AUTOSAR XML (schema 00046)
package /ComponentTypes
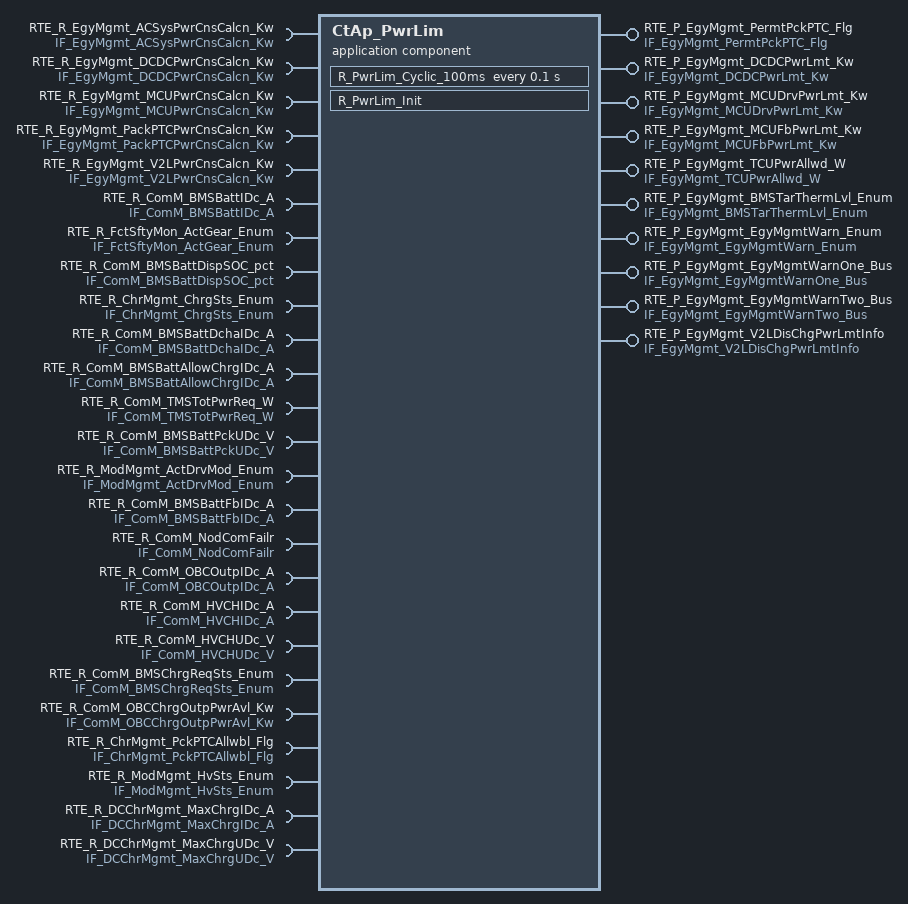
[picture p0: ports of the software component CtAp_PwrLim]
  application sw component type CtAp_PwrLim
    19 x require port:
      RTE_R_EgyMgmt_ACSysPwrCnsCalcn_Kw: nonqueued-receiver-com-spec{data-element=tec_EgyMgmt_ACSysPwrCnsCalcn_Kw, filter=data-filter-type=ALWAYS, init-value=0}, required-interface=IF_EgyMgmt_ACSysPwrCnsCalcn_Kw
      RTE_R_EgyMgmt_DCDCPwrCnsCalcn_Kw: nonqueued-receiver-com-spec{data-element=tec_EgyMgmt_DCDCPwrCnsCalcn_Kw, filter=data-filter-type=ALWAYS, init-value=0}, required-interface=IF_EgyMgmt_DCDCPwrCnsCalcn_Kw
      RTE_R_EgyMgmt_MCUPwrCnsCalcn_Kw: nonqueued-receiver-com-spec{data-element=tec_EgyMgmt_MCUPwrCnsCalcn_Kw, filter=data-filter-type=ALWAYS, init-value=0}, required-interface=IF_EgyMgmt_MCUPwrCnsCalcn_Kw
      RTE_R_EgyMgmt_PackPTCPwrCnsCalcn_Kw: nonqueued-receiver-com-spec{data-element=tec_EgyMgmt_PackPTCPwrCnsCalcn_Kw, filter=data-filter-type=ALWAYS, init-value=0}, required-interface=IF_EgyMgmt_PackPTCPwrCnsCalcn_Kw
      RTE_R_EgyMgmt_V2LPwrCnsCalcn_Kw: nonqueued-receiver-com-spec{data-element=tec_EgyMgmt_V2LPwrCnsCalcn_Kw, filter=data-filter-type=ALWAYS, init-value=0}, required-interface=IF_EgyMgmt_V2LPwrCnsCalcn_Kw
      RTE_R_ComM_BMSBattIDc_A: nonqueued-receiver-com-spec{data-element=tec_ComM_BMSBattIDc_A, filter=data-filter-type=ALWAYS, init-value=0}, required-interface=IF_ComM_BMSBattIDc_A
      RTE_R_FctSftyMon_ActGear_Enum: nonqueued-receiver-com-spec{data-element=tec_FctSftyMon_ActGear_Enum, filter=data-filter-type=ALWAYS, init-value=0}, required-interface=IF_FctSftyMon_ActGear_Enum
      RTE_R_ComM_BMSBattDispSOC_pct: nonqueued-receiver-com-spec{data-element=tec_ComM_BMSBattDispSOC_pct, filter=data-filter-type=ALWAYS, init-value=0}, required-interface=IF_ComM_BMSBattDispSOC_pct
      RTE_R_ChrMgmt_ChrgSts_Enum: nonqueued-receiver-com-spec{data-element=tec_ChrMgmt_ChrgSts_Enum, filter=data-filter-type=ALWAYS, init-value=0}, required-interface=IF_ChrMgmt_ChrgSts_Enum
      RTE_R_ComM_BMSBattDchaIDc_A: nonqueued-receiver-com-spec{data-element=tec_ComM_BMSBattDchaIDc_A, filter=data-filter-type=ALWAYS, init-value=0}, required-interface=IF_ComM_BMSBattDchaIDc_A
      RTE_R_ComM_BMSBattAllowChrgIDc_A: nonqueued-receiver-com-spec{data-element=tec_ComM_BMSBattAllowChrgIDc_A, filter=data-filter-type=ALWAYS, init-value=0}, required-interface=IF_ComM_BMSBattAllowChrgIDc_A
      RTE_R_ComM_TMSTotPwrReq_W: nonqueued-receiver-com-spec{data-element=tec_ComM_TMSTotPwrReq_W, filter=data-filter-type=ALWAYS, init-value=0}, required-interface=IF_ComM_TMSTotPwrReq_W
      RTE_R_ComM_BMSBattPckUDc_V: nonqueued-receiver-com-spec{data-element=tec_ComM_BMSBattPckUDc_V, filter=data-filter-type=ALWAYS, init-value=0}, required-interface=IF_ComM_BMSBattPckUDc_V
      RTE_R_ModMgmt_ActDrvMod_Enum: nonqueued-receiver-com-spec{data-element=tec_ModMgmt_ActDrvMod_Enum, filter=data-filter-type=ALWAYS, init-value=0}, required-interface=IF_ModMgmt_ActDrvMod_Enum
      RTE_R_ComM_BMSBattFbIDc_A: nonqueued-receiver-com-spec{data-element=tec_ComM_BMSBattFbIDc_A, filter=data-filter-type=ALWAYS, init-value=0}, required-interface=IF_ComM_BMSBattFbIDc_A
      RTE_R_ComM_NodComFailr: required-interface=IF_ComM_NodComFailr
        required-com-specs:
          data-element=tec_ComM_SGWNodComFailr_Flg, filter=data-filter-type=ALWAYS, init-value=0
          data-element=tec_ComM_CGWNodComFailr_Flg, filter=data-filter-type=ALWAYS, init-value=0
          data-element=tec_ComM_TCUNodComFailr_Flg, filter=data-filter-type=ALWAYS, init-value=0
          data-element=tec_ComM_BCMNodComFailr_Flg, filter=data-filter-type=ALWAYS, init-value=0
          data-element=tec_ComM_PRNDNodComFailr_Flg, filter=data-filter-type=ALWAYS, init-value=0
          data-element=tec_ComM_IVINodComFailr_Flg, filter=data-filter-type=ALWAYS, init-value=0
          data-element=tec_ComM_DCDCNodComFailr_Flg, filter=data-filter-type=ALWAYS, init-value=0
          data-element=tec_ComM_OBCNodComFailr_Flg, filter=data-filter-type=ALWAYS, init-value=0
          data-element=tec_ComM_CHIBSNodComFailr_Flg, filter=data-filter-type=ALWAYS, init-value=0
          data-element=tec_ComM_MCUNodComFailr_Flg, filter=data-filter-type=ALWAYS, init-value=0
          data-element=tec_ComM_EVCOMNodComFailr_Flg, filter=data-filter-type=ALWAYS, init-value=0
          data-element=tec_ComM_EPTIBSNodComFailr_Flg, filter=data-filter-type=ALWAYS, init-value=0
          data-element=tec_ComM_DCMNodComFailr_Flg, filter=data-filter-type=ALWAYS, init-value=0
          data-element=tec_ComM_BMSNodComFailr_Flg, filter=data-filter-type=ALWAYS, init-value=0
          data-element=tec_ComM_ACUNodComFailr_Flg, filter=data-filter-type=ALWAYS, init-value=0
          data-element=tec_ComM_APTCNodComFailr_Flg, filter=data-filter-type=ALWAYS, init-value=0
          data-element=tec_ComM_ADCUNodComFailr_Flg, filter=data-filter-type=ALWAYS, init-value=0
          data-element=tec_ComM_DCMRRNodComFailr_Flg, filter=data-filter-type=ALWAYS, init-value=0
          data-element=tec_ComM_DCMRLNodComFailr_Flg, filter=data-filter-type=ALWAYS, init-value=0
          data-element=tec_ComM_DCMFRNodComFailr_Flg, filter=data-filter-type=ALWAYS, init-value=0
          data-element=tec_ComM_DCMFLNodComFailr_Flg, filter=data-filter-type=ALWAYS, init-value=0
          data-element=tec_ComM_SGWCHNodComFailr_Flg, init-value=0
      RTE_R_ComM_OBCOutpIDc_A: nonqueued-receiver-com-spec{data-element=tec_ComM_OBCOutpIDc_A, filter=data-filter-type=ALWAYS, init-value=0}, required-interface=IF_ComM_OBCOutpIDc_A
      RTE_R_ComM_HVCHIDc_A: nonqueued-receiver-com-spec{data-element=tec_ComM_HVCHIDc_A, filter=data-filter-type=ALWAYS, init-value=0}, required-interface=IF_ComM_HVCHIDc_A
      RTE_R_ComM_HVCHUDc_V: nonqueued-receiver-com-spec{data-element=tec_ComM_HVCHUDc_V, filter=data-filter-type=ALWAYS, init-value=0}, required-interface=IF_ComM_HVCHUDc_V
    10 x provide port:
      RTE_P_EgyMgmt_PermtPckPTC_Flg: nonqueued-sender-com-spec{data-element=tec_EgyMgmt_PermtPckPTC_Flg, init-value=0}, provided-interface=IF_EgyMgmt_PermtPckPTC_Flg
      RTE_P_EgyMgmt_DCDCPwrLmt_Kw: nonqueued-sender-com-spec{data-element=tec_EgyMgmt_DCDCPwrLmt_Kw, init-value=0}, provided-interface=IF_EgyMgmt_DCDCPwrLmt_Kw
      RTE_P_EgyMgmt_MCUDrvPwrLmt_Kw: nonqueued-sender-com-spec{data-element=tec_EgyMgmt_MCUDrvPwrLmt_Kw, init-value=0}, provided-interface=IF_EgyMgmt_MCUDrvPwrLmt_Kw
      RTE_P_EgyMgmt_MCUFbPwrLmt_Kw: nonqueued-sender-com-spec{data-element=tec_EgyMgmt_MCUFbPwrLmt_Kw, init-value=0}, provided-interface=IF_EgyMgmt_MCUFbPwrLmt_Kw
      RTE_P_EgyMgmt_TCUPwrAllwd_W: nonqueued-sender-com-spec{data-element=tec_EgyMgmt_TCUPwrAllwd_W, init-value=0}, provided-interface=IF_EgyMgmt_TCUPwrAllwd_W
      RTE_P_EgyMgmt_BMSTarThermLvl_Enum: nonqueued-sender-com-spec{data-element=tec_EgyMgmt_BMSTarThermLvl_Enum, init-value=0}, provided-interface=IF_EgyMgmt_BMSTarThermLvl_Enum
      RTE_P_EgyMgmt_EgyMgmtWarn_Enum: nonqueued-sender-com-spec{data-element=tec_EgyMgmt_EgyMgmtWarn_Enum, init-value=0}, provided-interface=IF_EgyMgmt_EgyMgmtWarn_Enum
      RTE_P_EgyMgmt_EgyMgmtWarnOne_Bus: nonqueued-sender-com-spec{data-element=tec_EgyMgmt_EgyMgmtWarnOne_Bus, init-value=fields=[EgyMgmt_MonStatEgyMgmtWarnOne:0, EgyMgmt_MonResEgyMgmtWarnOne:0, EgyMgmt_ErrStatEgyMgmtWarnOne:0, EgyMgmt_ErrResEgyMgmtWarnOne:0]}, provided-interface=IF_EgyMgmt_EgyMgmtWarnOne_Bus
      RTE_P_EgyMgmt_EgyMgmtWarnTwo_Bus: nonqueued-sender-com-spec{data-element=tec_EgyMgmt_EgyMgmtWarnTwo_Bus, init-value=fields=[EgyMgmt_MonStatEgyMgmtWarnTwo:0, EgyMgmt_MonResEgyMgmtWarnTwo:0, EgyMgmt_ErrStatEgyMgmtWarnTwo:0, EgyMgmt_ErrResEgyMgmtWarnTwo:0]}, provided-interface=IF_EgyMgmt_EgyMgmtWarnTwo_Bus
      RTE_P_EgyMgmt_V2LDisChgPwrLmtInfo: nonqueued-sender-com-spec{data-element=tec_EgyMgmt_V2LDisChgPwrLmtInfo, init-value=0}, provided-interface=IF_EgyMgmt_V2LDisChgPwrLmtInfo
    6 x require port:
      RTE_R_ComM_BMSChrgReqSts_Enum: nonqueued-receiver-com-spec{data-element=tec_ComM_BMSChrgReqSts_Enum, filter=data-filter-type=ALWAYS, init-value=0}, required-interface=IF_ComM_BMSChrgReqSts_Enum
      RTE_R_ComM_OBCChrgOutpPwrAvl_Kw: nonqueued-receiver-com-spec{data-element=tec_ComM_OBCChrgOutpPwrAvl_Kw, filter=data-filter-type=ALWAYS, init-value=0}, required-interface=IF_ComM_OBCChrgOutpPwrAvl_Kw
      RTE_R_ChrMgmt_PckPTCAllwbl_Flg: nonqueued-receiver-com-spec{data-element=tec_ChrMgmt_PckPTCAllwbl_Flg, filter=data-filter-type=ALWAYS, init-value=0}, required-interface=IF_ChrMgmt_PckPTCAllwbl_Flg
      RTE_R_ModMgmt_HvSts_Enum: nonqueued-receiver-com-spec{data-element=tec_ModMgmt_HvSts_Enum, filter=data-filter-type=ALWAYS, init-value=0}, required-interface=IF_ModMgmt_HvSts_Enum
      RTE_R_DCChrMgmt_MaxChrgIDc_A: nonqueued-receiver-com-spec{data-element=tec_DCChrMgmt_MaxChrgIDc_A, filter=data-filter-type=ALWAYS, init-value=0}, required-interface=IF_DCChrMgmt_MaxChrgIDc_A
      RTE_R_DCChrMgmt_MaxChrgUDc_V: nonqueued-receiver-com-spec{data-element=tec_DCChrMgmt_MaxChrgUDc_V, filter=data-filter-type=ALWAYS, init-value=0}, required-interface=IF_DCChrMgmt_MaxChrgUDc_V
    behavior CtAp_PwrLim_InternalBehavior
      timing event TMT_R_PwrLim_Cyclic_100ms: start-on-event=R_PwrLim_Cyclic_100ms, period=0.1
      init event CtAp_PwrLim_InitEvent: start-on-event=R_PwrLim_Init
      runnable R_PwrLim_Cyclic_100ms
        data-receive-point-by-arguments:
          29 x access:
            REC_RTE_R_ChrMgmt_ChrgSts_Enum_tec_ChrMgmt_ChrgSts_Enum: accessed-variable=RTE_R_ChrMgmt_ChrgSts_Enum.tec_ChrMgmt_ChrgSts_Enum
            REC_RTE_R_ComM_BMSBattAllowChrgIDc_A_tec_ComM_BMSBattAllowChrgIDc_A: accessed-variable=RTE_R_ComM_BMSBattAllowChrgIDc_A.tec_ComM_BMSBattAllowChrgIDc_A
            REC_RTE_R_ComM_BMSBattDchaIDc_A_tec_ComM_BMSBattDchaIDc_A: accessed-variable=RTE_R_ComM_BMSBattDchaIDc_A.tec_ComM_BMSBattDchaIDc_A
            REC_RTE_R_ComM_BMSBattDispSOC_pct_tec_ComM_BMSBattDispSOC_pct: accessed-variable=RTE_R_ComM_BMSBattDispSOC_pct.tec_ComM_BMSBattDispSOC_pct
            REC_RTE_R_ComM_BMSBattFbIDc_A_tec_ComM_BMSBattFbIDc_A: accessed-variable=RTE_R_ComM_BMSBattFbIDc_A.tec_ComM_BMSBattFbIDc_A
            REC_RTE_R_ComM_BMSBattIDc_A_tec_ComM_BMSBattIDc_A: accessed-variable=RTE_R_ComM_BMSBattIDc_A.tec_ComM_BMSBattIDc_A
            REC_RTE_R_ComM_BMSBattPckUDc_V_tec_ComM_BMSBattPckUDc_V: accessed-variable=RTE_R_ComM_BMSBattPckUDc_V.tec_ComM_BMSBattPckUDc_V
            REC_RTE_R_ComM_HVCHIDc_A_tec_ComM_HVCHIDc_A: accessed-variable=RTE_R_ComM_HVCHIDc_A.tec_ComM_HVCHIDc_A
            REC_RTE_R_ComM_HVCHUDc_V_tec_ComM_HVCHUDc_V: accessed-variable=RTE_R_ComM_HVCHUDc_V.tec_ComM_HVCHUDc_V
            REC_RTE_R_ComM_NodComFailr_tec_ComM_BMSNodComFailr_Flg: accessed-variable=RTE_R_ComM_NodComFailr.tec_ComM_BMSNodComFailr_Flg
            REC_RTE_R_ComM_NodComFailr_tec_ComM_DCDCNodComFailr_Flg: accessed-variable=RTE_R_ComM_NodComFailr.tec_ComM_DCDCNodComFailr_Flg
            REC_RTE_R_ComM_NodComFailr_tec_ComM_MCUNodComFailr_Flg: accessed-variable=RTE_R_ComM_NodComFailr.tec_ComM_MCUNodComFailr_Flg
            REC_RTE_R_ComM_NodComFailr_tec_ComM_TCUNodComFailr_Flg: accessed-variable=RTE_R_ComM_NodComFailr.tec_ComM_TCUNodComFailr_Flg
            REC_RTE_R_ComM_OBCOutpIDc_A_tec_ComM_OBCOutpIDc_A: accessed-variable=RTE_R_ComM_OBCOutpIDc_A.tec_ComM_OBCOutpIDc_A
            REC_RTE_R_ComM_TMSTotPwrReq_W_tec_ComM_TMSTotPwrReq_W: accessed-variable=RTE_R_ComM_TMSTotPwrReq_W.tec_ComM_TMSTotPwrReq_W
            REC_RTE_R_EgyMgmt_ACSysPwrCnsCalcn_Kw_tec_EgyMgmt_ACSysPwrCnsCalcn_Kw: accessed-variable=RTE_R_EgyMgmt_ACSysPwrCnsCalcn_Kw.tec_EgyMgmt_ACSysPwrCnsCalcn_Kw
            REC_RTE_R_EgyMgmt_DCDCPwrCnsCalcn_Kw_tec_EgyMgmt_DCDCPwrCnsCalcn_Kw: accessed-variable=RTE_R_EgyMgmt_DCDCPwrCnsCalcn_Kw.tec_EgyMgmt_DCDCPwrCnsCalcn_Kw
            REC_RTE_R_EgyMgmt_MCUPwrCnsCalcn_Kw_tec_EgyMgmt_MCUPwrCnsCalcn_Kw: accessed-variable=RTE_R_EgyMgmt_MCUPwrCnsCalcn_Kw.tec_EgyMgmt_MCUPwrCnsCalcn_Kw
            REC_RTE_R_EgyMgmt_PackPTCPwrCnsCalcn_Kw_tec_EgyMgmt_PackPTCPwrCnsCalcn_Kw: accessed-variable=RTE_R_EgyMgmt_PackPTCPwrCnsCalcn_Kw.tec_EgyMgmt_PackPTCPwrCnsCalcn_Kw
            REC_RTE_R_EgyMgmt_V2LPwrCnsCalcn_Kw_tec_EgyMgmt_V2LPwrCnsCalcn_Kw: accessed-variable=RTE_R_EgyMgmt_V2LPwrCnsCalcn_Kw.tec_EgyMgmt_V2LPwrCnsCalcn_Kw
            REC_RTE_R_FctSftyMon_ActGear_Enum_tec_FctSftyMon_ActGear_Enum: accessed-variable=RTE_R_FctSftyMon_ActGear_Enum.tec_FctSftyMon_ActGear_Enum
            REC_RTE_R_ModMgmt_ActDrvMod_Enum_tec_ModMgmt_ActDrvMod_Enum: accessed-variable=RTE_R_ModMgmt_ActDrvMod_Enum.tec_ModMgmt_ActDrvMod_Enum
            REC_RTE_R_ComM_NodComFailr_tec_ComM_OBCNodComFailr_Flg: accessed-variable=RTE_R_ComM_NodComFailr.tec_ComM_OBCNodComFailr_Flg
            REC_RTE_R_ChrMgmt_PckPTCAllwbl_Flg_tec_ChrMgmt_PckPTCAllwbl_Flg: accessed-variable=RTE_R_ChrMgmt_PckPTCAllwbl_Flg.tec_ChrMgmt_PckPTCAllwbl_Flg
            REC_RTE_R_ComM_BMSChrgReqSts_Enum_tec_ComM_BMSChrgReqSts_Enum: accessed-variable=RTE_R_ComM_BMSChrgReqSts_Enum.tec_ComM_BMSChrgReqSts_Enum
            REC_RTE_R_ComM_OBCChrgOutpPwrAvl_Kw_tec_ComM_OBCChrgOutpPwrAvl_Kw: accessed-variable=RTE_R_ComM_OBCChrgOutpPwrAvl_Kw.tec_ComM_OBCChrgOutpPwrAvl_Kw
            REC_RTE_R_ModMgmt_HvSts_Enum_tec_ModMgmt_HvSts_Enum: accessed-variable=RTE_R_ModMgmt_HvSts_Enum.tec_ModMgmt_HvSts_Enum
            REC_RTE_R_DCChrMgmt_MaxChrgIDc_A_tec_DCChrMgmt_MaxChrgIDc_A: accessed-variable=RTE_R_DCChrMgmt_MaxChrgIDc_A.tec_DCChrMgmt_MaxChrgIDc_A
            REC_RTE_R_DCChrMgmt_MaxChrgUDc_V_tec_DCChrMgmt_MaxChrgUDc_V: accessed-variable=RTE_R_DCChrMgmt_MaxChrgUDc_V.tec_DCChrMgmt_MaxChrgUDc_V
        data-send-points:
          10 x access:
            SEND_RTE_P_EgyMgmt_BMSTarThermLvl_Enum_tec_EgyMgmt_BMSTarThermLvl_Enum: accessed-variable=RTE_P_EgyMgmt_BMSTarThermLvl_Enum.tec_EgyMgmt_BMSTarThermLvl_Enum
            SEND_RTE_P_EgyMgmt_DCDCPwrLmt_Kw_tec_EgyMgmt_DCDCPwrLmt_Kw: accessed-variable=RTE_P_EgyMgmt_DCDCPwrLmt_Kw.tec_EgyMgmt_DCDCPwrLmt_Kw
            SEND_RTE_P_EgyMgmt_EgyMgmtWarnOne_Bus_tec_EgyMgmt_EgyMgmtWarnOne_Bus: accessed-variable=RTE_P_EgyMgmt_EgyMgmtWarnOne_Bus.tec_EgyMgmt_EgyMgmtWarnOne_Bus
            SEND_RTE_P_EgyMgmt_EgyMgmtWarnTwo_Bus_tec_EgyMgmt_EgyMgmtWarnTwo_Bus: accessed-variable=RTE_P_EgyMgmt_EgyMgmtWarnTwo_Bus.tec_EgyMgmt_EgyMgmtWarnTwo_Bus
            SEND_RTE_P_EgyMgmt_EgyMgmtWarn_Enum_tec_EgyMgmt_EgyMgmtWarn_Enum: accessed-variable=RTE_P_EgyMgmt_EgyMgmtWarn_Enum.tec_EgyMgmt_EgyMgmtWarn_Enum
            SEND_RTE_P_EgyMgmt_MCUDrvPwrLmt_Kw_tec_EgyMgmt_MCUDrvPwrLmt_Kw: accessed-variable=RTE_P_EgyMgmt_MCUDrvPwrLmt_Kw.tec_EgyMgmt_MCUDrvPwrLmt_Kw
            SEND_RTE_P_EgyMgmt_MCUFbPwrLmt_Kw_tec_EgyMgmt_MCUFbPwrLmt_Kw: accessed-variable=RTE_P_EgyMgmt_MCUFbPwrLmt_Kw.tec_EgyMgmt_MCUFbPwrLmt_Kw
            SEND_RTE_P_EgyMgmt_PermtPckPTC_Flg_tec_EgyMgmt_PermtPckPTC_Flg: accessed-variable=RTE_P_EgyMgmt_PermtPckPTC_Flg.tec_EgyMgmt_PermtPckPTC_Flg
            SEND_RTE_P_EgyMgmt_TCUPwrAllwd_W_tec_EgyMgmt_TCUPwrAllwd_W: accessed-variable=RTE_P_EgyMgmt_TCUPwrAllwd_W.tec_EgyMgmt_TCUPwrAllwd_W
            SEND_RTE_P_EgyMgmt_V2LDisChgPwrLmtInfo_tec_EgyMgmt_V2LDisChgPwrLmtInfo: accessed-variable=RTE_P_EgyMgmt_V2LDisChgPwrLmtInfo.tec_EgyMgmt_V2LDisChgPwrLmtInfo
      runnable R_PwrLim_Init
  swc implementation CtAp_PwrLim_Implementation: behavior=CtAp_PwrLim_InternalBehavior
